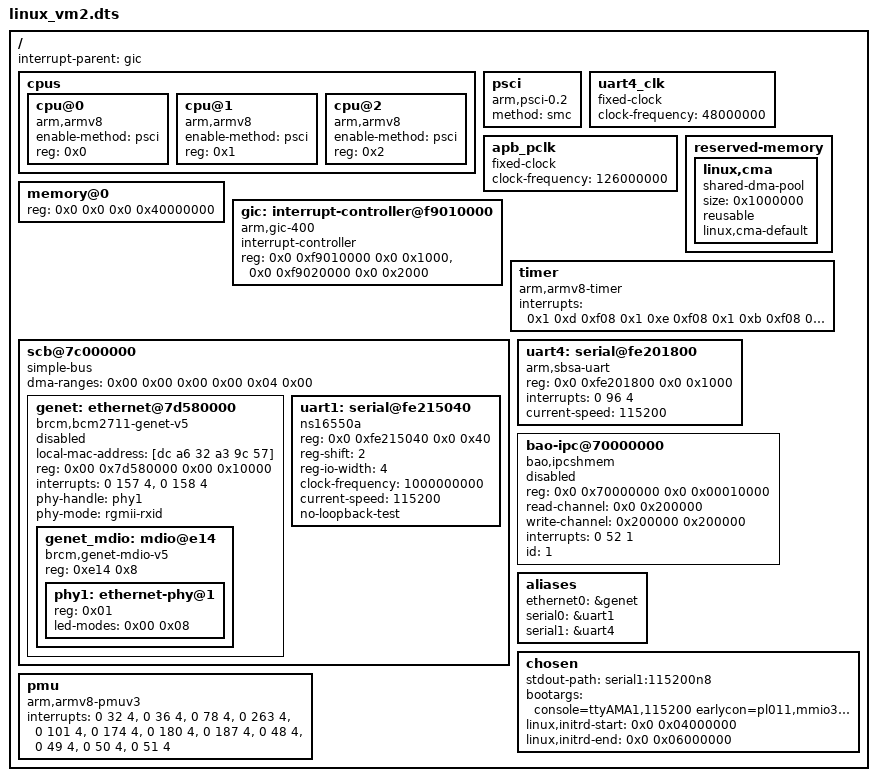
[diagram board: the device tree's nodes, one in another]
/dts-v1/;

/ {
    #address-cells = <2>;
    #size-cells = <2>;
    interrupt-parent = <&gic>;

    cpus {
        #size-cells = <0x0>;
        #address-cells = <0x1>;

        cpu@0 {
            compatible = "arm,armv8";
            device_type = "cpu";
            enable-method = "psci";
            reg = <0x0>;
        };

        cpu@1 {
            compatible = "arm,armv8";
            device_type = "cpu";
            enable-method = "psci";
            reg = <0x1>;
        };

        cpu@2 {
            compatible = "arm,armv8";
            device_type = "cpu";
            enable-method = "psci";
            reg = <0x2>;
        };

    };

    psci {
        compatible = "arm,psci-0.2";
        method = "smc";
    };

    uart4_clk: uart4_clk {
        compatible = "fixed-clock";
        #clock-cells = <0>;
        clock-frequency = <48000000>;
    };

    apb_pclk: apb_pclk {
        compatible = "fixed-clock";
        #clock-cells = <0>;
        clock-frequency = <126000000>;
    };

    memory@0 {
        reg = <0x0 0x0 0x0 0x40000000>;
        device_type = "memory";
    };

    reserved-memory {
        #address-cells = <0x02>;
        #size-cells = <0x01>;
        ranges;

        linux,cma {
            compatible = "shared-dma-pool";
            size = <0x1000000>;
            reusable;
            linux,cma-default;
        };
    };

    gic: interrupt-controller@f9010000 {
        compatible = "arm,gic-400";
        #interrupt-cells = <3>;
        interrupt-controller;
        reg = <0x0 0xf9010000 0x0 0x1000>,
              <0x0 0xf9020000 0x0 0x2000>;
    };

    timer {
        compatible = "arm,armv8-timer";
        interrupts = <0x1 0xd 0xf08 0x1 0xe 0xf08 0x1 0xb 0xf08 0x1 0xa 0xf08>;
    };

    scb@7c000000 {
        compatible = "simple-bus";
        #address-cells = <0x02>;
        #size-cells = < 0x02 >;
        dma-ranges = < 0x00 0x00 0x00 0x00 0x04 0x00 >;
        ranges;

        genet: ethernet@7d580000 {
            local-mac-address = [dc a6 32 a3 9c 57];
            compatible = "brcm,bcm2711-genet-v5", "brcm,genet-v5";
            reg = < 0x00 0x7d580000 0x00 0x10000 >;
            #address-cells = <0x1>;
            #size-cells = <0x1>;
            interrupts = <0 157 4>,
                        <0 158 4>;
            status = "disabled";

            phy-handle = <&phy1>;
            phy-mode = "rgmii-rxid";

            genet_mdio: mdio@e14 {
                compatible = "brcm,genet-mdio-v5";
                reg = <0xe14 0x8>;
                reg-names = "mdio";
                #address-cells = <0x0>;
                #size-cells = <0x1>;

                phy1: ethernet-phy@1 {
                    reg = <0x01>;
                    led-modes = < 0x00 0x08 >;
                };
            };
        };

        uart1:serial@fe215040 {
            compatible = "ns16550a";
            reg = <0x0 0xfe215040 0x0 0x40>;
            reg-shift = <2>;
            reg-io-width = <4>;
            clock-frequency = <1000000000>;
            current-speed = <115200>;
            no-loopback-test;
            status = "okay";
        };
    };

    uart4:serial@fe201800 {
        compatible = "arm,sbsa-uart";
        reg = <0x0 0xfe201800 0x0 0x1000>;
        interrupts = <0 96 4>;
        current-speed = <115200>;
        status = "okay";
    };

    bao-ipc@70000000 {
        compatible = "bao,ipcshmem";
        reg = <0x0 0x70000000 0x0 0x00010000>;
        read-channel = <0x0 0x200000>;
        write-channel = <0x200000 0x200000>;
        interrupts = <0 52 1>;
        id = <1>;
        status = "disabled";
    };

    aliases {
        ethernet0 = &genet;
        serial0 = &uart1;
        serial1 = &uart4;
    };

    chosen {
        stdout-path = "serial1:115200n8";
        bootargs = "console=ttyAMA1,115200 earlycon=pl011,mmio32,0xfe201800 clk_ignore_unused fw_devlink=permissive ip=192.168.2.5 carrier_timeout=0 vm_role=apparate";
        linux,initrd-start = <0x0 0x04000000>;
        linux,initrd-end   = <0x0 0x06000000>; /* SED_PLACEHOLDER */
    };

    pmu {
        compatible = "arm,armv8-pmuv3";
        interrupts = <0 32 4>,
                     <0 36 4>,
                      <0 78 4>,
                     <0 263 4>,
                     <0 101 4>,
                     <0 174 4>,
                     <0 180 4>,
                     <0 187 4>,
                     <0 48 4>,
                     <0 49 4>,
                     <0 50 4>,
                     <0 51 4>;
    };

};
